# MAIN_IP_ECC_AGGR0_ECC_AGGR register map
Vendor: Texas Instruments
Registers are 32-bit, access not given, reset 0x0 unless marked. A register's access mark holds for its fields unless they carry their own. Offsets are as the file gives them; [hi:lo] are bit positions.

## MAIN_IP_ECC_AGGR0_ECC_AGGR (part 2 of 4)
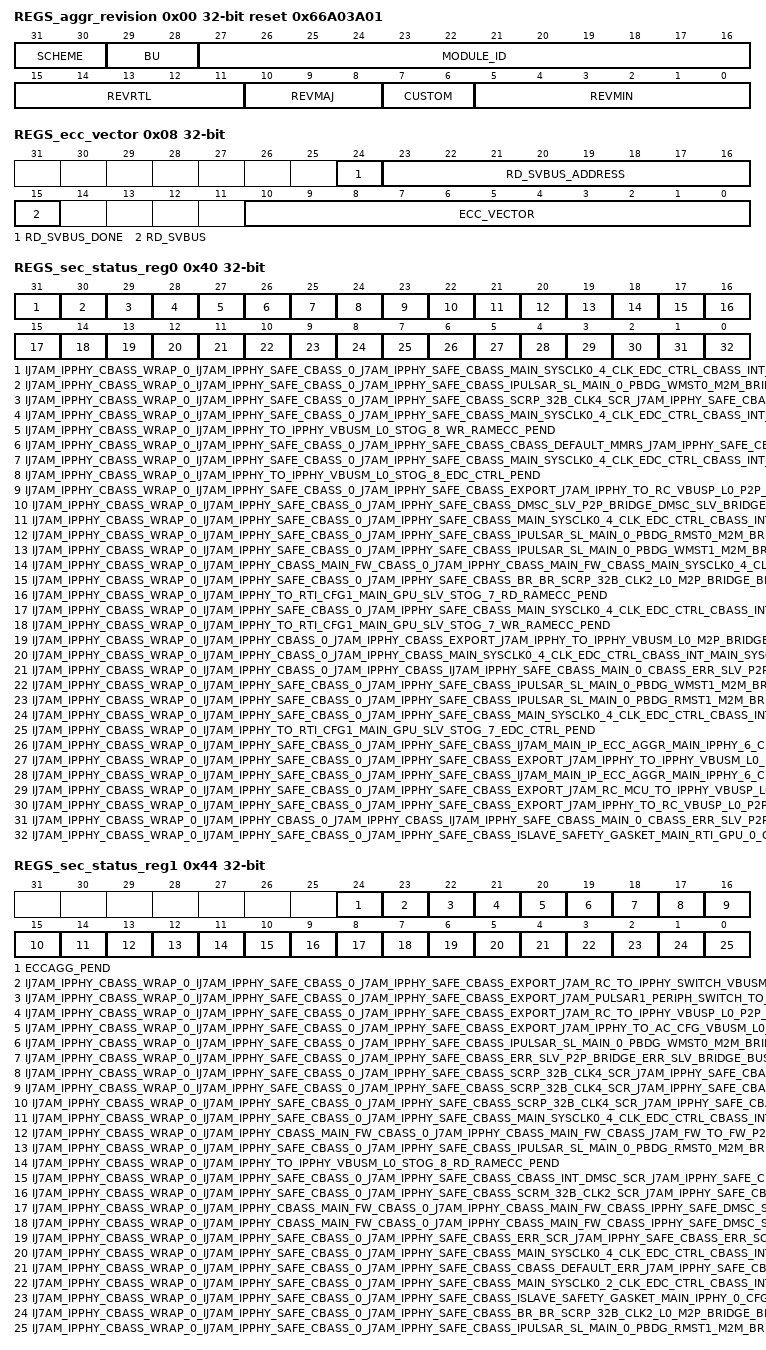
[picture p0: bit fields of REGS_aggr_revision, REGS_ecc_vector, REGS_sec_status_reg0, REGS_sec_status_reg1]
0x00 REGS_aggr_revision ro reset 0x66A03A01 — Revision parameters
  [31:30] SCHEME
  [29:28] BU
  [27:16] MODULE_ID
  [15:11] REVRTL — RTL version
  [10:8] REVMAJ — Major version
  [7:6] CUSTOM — Custom version
  [5:0] REVMIN — Minor version
0x08 REGS_ecc_vector — ECC Vector Register
  [24] RD_SVBUS_DONE — Status to indicate if read on serial VBUS is complete, write of any value will clear this bit. (access R/W1TC)
  [23:16] RD_SVBUS_ADDRESS rw — Read address
  [15] RD_SVBUS — Write 1 to trigger a read on the serial VBUS (access R/W1TS)
  [10:0] ECC_VECTOR rw — Value written to select the corresponding ECC RAM for control or status
0x0C REGS_misc_status ro reset 0x39 — Misc Status
  [10:0] NUM_RAMS — Indicates the number of RAMS serviced by the ECC aggregator
0x10 REGS_reserved_svbus rw — Reference other documents that contain the ECC RAM wrapper and EDC controller serial vbus register sets.
  [31:0] DATA — Serial VBUS register data
0x3C REGS_sec_eoi_reg — EOI Register
  [0] EOI_WR — EOI Register (access R/W1TS)
0x40 REGS_sec_status_reg0 — Interrupt Status Register 0
  [31] IJ7AM_IPPHY_CBASS_WRAP_0_IJ7AM_IPPHY_SAFE_CBASS_0_J7AM_IPPHY_SAFE_CBASS_MAIN_SYSCLK0_4_CLK_EDC_CTRL_CBASS_INT_MAIN_SYSCLK0_4_BUSECC_3_PEND — Interrupt Pending Status for Ij7am_ipphy_cbass_wrap_0_Ij7am_ipphy_safe_cbass_0_j7am_ipphy_safe_cbass_main_SYSCLK0_4_clk_edc_ctrl_cbass_int_main_SYSCLK0_4_busecc_3_pend (access R/W1TS)
  [30] IJ7AM_IPPHY_CBASS_WRAP_0_IJ7AM_IPPHY_SAFE_CBASS_0_J7AM_IPPHY_SAFE_CBASS_IPULSAR_SL_MAIN_0_PBDG_WMST0_M2M_BRIDGE_J7AM_IPPHY_SAFE_CBASS_IPULSAR_SL_MAIN_0_PBDG_WMST0_M2M_BRIDGE_SRC_EDC_CTRL_BUSECC_PEND — Interrupt Pending Status for Ij7am_ipphy_cbass_wrap_0_Ij7am_ipphy_safe_cbass_0_j7am_ipphy_safe_cbass_Ipulsar_sl_main_0_pbdg_wmst0_m2m_bridge_j7am_ipphy_safe_cbass_Ipulsar_sl_main_0_pbdg_wmst0_m2m_bridge_src_edc_ctrl_busecc_pend (access R/W1TS)
  [29] IJ7AM_IPPHY_CBASS_WRAP_0_IJ7AM_IPPHY_SAFE_CBASS_0_J7AM_IPPHY_SAFE_CBASS_SCRP_32B_CLK4_SCR_J7AM_IPPHY_SAFE_CBASS_SCRP_32B_CLK4_SCR_EDC_CTRL_BUSECC_0_PEND — Interrupt Pending Status for Ij7am_ipphy_cbass_wrap_0_Ij7am_ipphy_safe_cbass_0_j7am_ipphy_safe_cbass_scrp_32b_clk4_scr_j7am_ipphy_safe_cbass_scrp_32b_clk4_scr_edc_ctrl_busecc_0_pend (access R/W1TS)
  [28] IJ7AM_IPPHY_CBASS_WRAP_0_IJ7AM_IPPHY_SAFE_CBASS_0_J7AM_IPPHY_SAFE_CBASS_MAIN_SYSCLK0_4_CLK_EDC_CTRL_CBASS_INT_MAIN_SYSCLK0_4_BUSECC_5_PEND — Interrupt Pending Status for Ij7am_ipphy_cbass_wrap_0_Ij7am_ipphy_safe_cbass_0_j7am_ipphy_safe_cbass_main_SYSCLK0_4_clk_edc_ctrl_cbass_int_main_SYSCLK0_4_busecc_5_pend (access R/W1TS)
  [27] IJ7AM_IPPHY_CBASS_WRAP_0_IJ7AM_IPPHY_TO_IPPHY_VBUSM_L0_STOG_8_WR_RAMECC_PEND — Interrupt Pending Status for Ij7am_ipphy_cbass_wrap_0_Ij7am_ipphy_to_ipphy_vbusm_l0_stog_8_wr_ramecc_pend (access R/W1TS)
  [26] IJ7AM_IPPHY_CBASS_WRAP_0_IJ7AM_IPPHY_SAFE_CBASS_0_J7AM_IPPHY_SAFE_CBASS_CBASS_DEFAULT_MMRS_J7AM_IPPHY_SAFE_CBASS_CBASS_DEFAULT_MMRS_EDC_CTRL_BUSECC_PEND — Interrupt Pending Status for Ij7am_ipphy_cbass_wrap_0_Ij7am_ipphy_safe_cbass_0_j7am_ipphy_safe_cbass_cbass_default_mmrs_j7am_ipphy_safe_cbass_cbass_default_mmrs_edc_ctrl_busecc_pend (access R/W1TS)
  [25] IJ7AM_IPPHY_CBASS_WRAP_0_IJ7AM_IPPHY_SAFE_CBASS_0_J7AM_IPPHY_SAFE_CBASS_MAIN_SYSCLK0_4_CLK_EDC_CTRL_CBASS_INT_MAIN_SYSCLK0_4_BUSECC_0_PEND — Interrupt Pending Status for Ij7am_ipphy_cbass_wrap_0_Ij7am_ipphy_safe_cbass_0_j7am_ipphy_safe_cbass_main_SYSCLK0_4_clk_edc_ctrl_cbass_int_main_SYSCLK0_4_busecc_0_pend (access R/W1TS)
  [24] IJ7AM_IPPHY_CBASS_WRAP_0_IJ7AM_IPPHY_TO_IPPHY_VBUSM_L0_STOG_8_EDC_CTRL_PEND — Interrupt Pending Status for Ij7am_ipphy_cbass_wrap_0_Ij7am_ipphy_to_ipphy_vbusm_l0_stog_8_edc_ctrl_pend (access R/W1TS)
  [23] IJ7AM_IPPHY_CBASS_WRAP_0_IJ7AM_IPPHY_SAFE_CBASS_0_J7AM_IPPHY_SAFE_CBASS_EXPORT_J7AM_IPPHY_TO_RC_VBUSP_L0_P2P_BRIDGE_EXPORT_J7AM_IPPHY_TO_RC_VBUSP_L0_BRIDGE_DST_BUSECC_PEND — Interrupt Pending Status for Ij7am_ipphy_cbass_wrap_0_Ij7am_ipphy_safe_cbass_0_j7am_ipphy_safe_cbass_export_j7am_ipphy_to_rc_vbusp_l0_p2p_bridge_export_j7am_ipphy_to_rc_vbusp_l0_bridge_dst_busecc_pend (access R/W1TS)
  [22] IJ7AM_IPPHY_CBASS_WRAP_0_IJ7AM_IPPHY_SAFE_CBASS_0_J7AM_IPPHY_SAFE_CBASS_DMSC_SLV_P2P_BRIDGE_DMSC_SLV_BRIDGE_BUSECC_PEND — Interrupt Pending Status for Ij7am_ipphy_cbass_wrap_0_Ij7am_ipphy_safe_cbass_0_j7am_ipphy_safe_cbass_dmsc_slv_p2p_bridge_dmsc_slv_bridge_busecc_pend (access R/W1TS)
  [21] IJ7AM_IPPHY_CBASS_WRAP_0_IJ7AM_IPPHY_SAFE_CBASS_0_J7AM_IPPHY_SAFE_CBASS_MAIN_SYSCLK0_4_CLK_EDC_CTRL_CBASS_INT_MAIN_SYSCLK0_4_BUSECC_4_PEND — Interrupt Pending Status for Ij7am_ipphy_cbass_wrap_0_Ij7am_ipphy_safe_cbass_0_j7am_ipphy_safe_cbass_main_SYSCLK0_4_clk_edc_ctrl_cbass_int_main_SYSCLK0_4_busecc_4_pend (access R/W1TS)
  [20] IJ7AM_IPPHY_CBASS_WRAP_0_IJ7AM_IPPHY_SAFE_CBASS_0_J7AM_IPPHY_SAFE_CBASS_IPULSAR_SL_MAIN_0_PBDG_RMST0_M2M_BRIDGE_J7AM_IPPHY_SAFE_CBASS_IPULSAR_SL_MAIN_0_PBDG_RMST0_M2M_BRIDGE_SRC_EDC_CTRL_BUSECC_PEND — Interrupt Pending Status for Ij7am_ipphy_cbass_wrap_0_Ij7am_ipphy_safe_cbass_0_j7am_ipphy_safe_cbass_Ipulsar_sl_main_0_pbdg_rmst0_m2m_bridge_j7am_ipphy_safe_cbass_Ipulsar_sl_main_0_pbdg_rmst0_m2m_bridge_src_edc_ctrl_busecc_pend (access R/W1TS)
  [19] IJ7AM_IPPHY_CBASS_WRAP_0_IJ7AM_IPPHY_SAFE_CBASS_0_J7AM_IPPHY_SAFE_CBASS_IPULSAR_SL_MAIN_0_PBDG_WMST1_M2M_BRIDGE_J7AM_IPPHY_SAFE_CBASS_IPULSAR_SL_MAIN_0_PBDG_WMST1_M2M_BRIDGE_SRC_EDC_CTRL_BUSECC_PEND — Interrupt Pending Status for Ij7am_ipphy_cbass_wrap_0_Ij7am_ipphy_safe_cbass_0_j7am_ipphy_safe_cbass_Ipulsar_sl_main_0_pbdg_wmst1_m2m_bridge_j7am_ipphy_safe_cbass_Ipulsar_sl_main_0_pbdg_wmst1_m2m_bridge_src_edc_ctrl_busecc_pend (access R/W1TS)
  [18] IJ7AM_IPPHY_CBASS_WRAP_0_IJ7AM_IPPHY_CBASS_MAIN_FW_CBASS_0_J7AM_IPPHY_CBASS_MAIN_FW_CBASS_MAIN_SYSCLK0_4_CLK_EDC_CTRL_CBASS_INT_MAIN_SYSCLK0_4_BUSECC_PEND — Interrupt Pending Status for Ij7am_ipphy_cbass_wrap_0_Ij7am_ipphy_cbass_main_fw_cbass_0_j7am_ipphy_cbass_main_fw_cbass_main_SYSCLK0_4_clk_edc_ctrl_cbass_int_main_SYSCLK0_4_busecc_pend (access R/W1TS)
  [17] IJ7AM_IPPHY_CBASS_WRAP_0_IJ7AM_IPPHY_SAFE_CBASS_0_J7AM_IPPHY_SAFE_CBASS_BR_BR_SCRP_32B_CLK2_L0_M2P_BRIDGE_BR_BR_SCRP_32B_CLK2_L0_BRIDGE_SRC_BUSECC_PEND — Interrupt Pending Status for Ij7am_ipphy_cbass_wrap_0_Ij7am_ipphy_safe_cbass_0_j7am_ipphy_safe_cbass_br_br_scrp_32b_clk2_l0_m2p_bridge_br_br_scrp_32b_clk2_l0_bridge_src_busecc_pend (access R/W1TS)
  [16] IJ7AM_IPPHY_CBASS_WRAP_0_IJ7AM_IPPHY_TO_RTI_CFG1_MAIN_GPU_SLV_STOG_7_RD_RAMECC_PEND — Interrupt Pending Status for Ij7am_ipphy_cbass_wrap_0_Ij7am_ipphy_to_rti_cfg1_main_gpu_slv_stog_7_rd_ramecc_pend (access R/W1TS)
  [15] IJ7AM_IPPHY_CBASS_WRAP_0_IJ7AM_IPPHY_SAFE_CBASS_0_J7AM_IPPHY_SAFE_CBASS_MAIN_SYSCLK0_4_CLK_EDC_CTRL_CBASS_INT_MAIN_SYSCLK0_4_BUSECC_6_PEND — Interrupt Pending Status for Ij7am_ipphy_cbass_wrap_0_Ij7am_ipphy_safe_cbass_0_j7am_ipphy_safe_cbass_main_SYSCLK0_4_clk_edc_ctrl_cbass_int_main_SYSCLK0_4_busecc_6_pend (access R/W1TS)
  [14] IJ7AM_IPPHY_CBASS_WRAP_0_IJ7AM_IPPHY_TO_RTI_CFG1_MAIN_GPU_SLV_STOG_7_WR_RAMECC_PEND — Interrupt Pending Status for Ij7am_ipphy_cbass_wrap_0_Ij7am_ipphy_to_rti_cfg1_main_gpu_slv_stog_7_wr_ramecc_pend (access R/W1TS)
  [13] IJ7AM_IPPHY_CBASS_WRAP_0_IJ7AM_IPPHY_CBASS_0_J7AM_IPPHY_CBASS_EXPORT_J7AM_IPPHY_TO_IPPHY_VBUSM_L0_M2P_BRIDGE_EXPORT_J7AM_IPPHY_TO_IPPHY_VBUSM_L0_BRIDGE_BUSECC_PEND — Interrupt Pending Status for Ij7am_ipphy_cbass_wrap_0_Ij7am_ipphy_cbass_0_j7am_ipphy_cbass_export_j7am_ipphy_to_ipphy_vbusm_l0_m2p_bridge_export_j7am_ipphy_to_ipphy_vbusm_l0_bridge_busecc_pend (access R/W1TS)
  [12] IJ7AM_IPPHY_CBASS_WRAP_0_IJ7AM_IPPHY_CBASS_0_J7AM_IPPHY_CBASS_MAIN_SYSCLK0_4_CLK_EDC_CTRL_CBASS_INT_MAIN_SYSCLK0_4_BUSECC_PEND — Interrupt Pending Status for Ij7am_ipphy_cbass_wrap_0_Ij7am_ipphy_cbass_0_j7am_ipphy_cbass_main_SYSCLK0_4_clk_edc_ctrl_cbass_int_main_SYSCLK0_4_busecc_pend (access R/W1TS)
  [11] IJ7AM_IPPHY_CBASS_WRAP_0_IJ7AM_IPPHY_CBASS_0_J7AM_IPPHY_CBASS_IJ7AM_IPPHY_SAFE_CBASS_MAIN_0_CBASS_ERR_SLV_P2P_BRIDGE_IJ7AM_IPPHY_SAFE_CBASS_MAIN_0_CBASS_ERR_SLV_BRIDGE_DST_BUSECC_PEND — Interrupt Pending Status for Ij7am_ipphy_cbass_wrap_0_Ij7am_ipphy_cbass_0_j7am_ipphy_cbass_Ij7am_ipphy_safe_cbass_main_0_cbass_err_slv_p2p_bridge_Ij7am_ipphy_safe_cbass_main_0_cbass_err_slv_bridge_dst_busecc_pend (access R/W1TS)
  [10] IJ7AM_IPPHY_CBASS_WRAP_0_IJ7AM_IPPHY_SAFE_CBASS_0_J7AM_IPPHY_SAFE_CBASS_IPULSAR_SL_MAIN_0_PBDG_WMST1_M2M_BRIDGE_J7AM_IPPHY_SAFE_CBASS_IPULSAR_SL_MAIN_0_PBDG_WMST1_M2M_BRIDGE_DST_EDC_CTRL_BUSECC_PEND — Interrupt Pending Status for Ij7am_ipphy_cbass_wrap_0_Ij7am_ipphy_safe_cbass_0_j7am_ipphy_safe_cbass_Ipulsar_sl_main_0_pbdg_wmst1_m2m_bridge_j7am_ipphy_safe_cbass_Ipulsar_sl_main_0_pbdg_wmst1_m2m_bridge_dst_edc_ctrl_busecc_pend (access R/W1TS)
  [9] IJ7AM_IPPHY_CBASS_WRAP_0_IJ7AM_IPPHY_SAFE_CBASS_0_J7AM_IPPHY_SAFE_CBASS_IPULSAR_SL_MAIN_0_PBDG_RMST1_M2M_BRIDGE_J7AM_IPPHY_SAFE_CBASS_IPULSAR_SL_MAIN_0_PBDG_RMST1_M2M_BRIDGE_SRC_EDC_CTRL_BUSECC_PEND — Interrupt Pending Status for Ij7am_ipphy_cbass_wrap_0_Ij7am_ipphy_safe_cbass_0_j7am_ipphy_safe_cbass_Ipulsar_sl_main_0_pbdg_rmst1_m2m_bridge_j7am_ipphy_safe_cbass_Ipulsar_sl_main_0_pbdg_rmst1_m2m_bridge_src_edc_ctrl_busecc_pend (access R/W1TS)
  [8] IJ7AM_IPPHY_CBASS_WRAP_0_IJ7AM_IPPHY_SAFE_CBASS_0_J7AM_IPPHY_SAFE_CBASS_MAIN_SYSCLK0_4_CLK_EDC_CTRL_CBASS_INT_MAIN_SYSCLK0_4_BUSECC_7_PEND — Interrupt Pending Status for Ij7am_ipphy_cbass_wrap_0_Ij7am_ipphy_safe_cbass_0_j7am_ipphy_safe_cbass_main_SYSCLK0_4_clk_edc_ctrl_cbass_int_main_SYSCLK0_4_busecc_7_pend (access R/W1TS)
  [7] IJ7AM_IPPHY_CBASS_WRAP_0_IJ7AM_IPPHY_TO_RTI_CFG1_MAIN_GPU_SLV_STOG_7_EDC_CTRL_PEND — Interrupt Pending Status for Ij7am_ipphy_cbass_wrap_0_Ij7am_ipphy_to_rti_cfg1_main_gpu_slv_stog_7_edc_ctrl_pend (access R/W1TS)
  [6] IJ7AM_IPPHY_CBASS_WRAP_0_IJ7AM_IPPHY_SAFE_CBASS_0_J7AM_IPPHY_SAFE_CBASS_IJ7AM_MAIN_IP_ECC_AGGR_MAIN_IPPHY_6_CFG_P2P_BRIDGE_IJ7AM_MAIN_IP_ECC_AGGR_MAIN_IPPHY_6_CFG_BRIDGE_SRC_BUSECC_PEND — Interrupt Pending Status for Ij7am_ipphy_cbass_wrap_0_Ij7am_ipphy_safe_cbass_0_j7am_ipphy_safe_cbass_Ij7am_main_ip_ecc_aggr_main_ipphy_6_cfg_p2p_bridge_Ij7am_main_ip_ecc_aggr_main_ipphy_6_cfg_bridge_src_busecc_pend (access R/W1TS)
  [5] IJ7AM_IPPHY_CBASS_WRAP_0_IJ7AM_IPPHY_SAFE_CBASS_0_J7AM_IPPHY_SAFE_CBASS_EXPORT_J7AM_IPPHY_TO_IPPHY_VBUSM_L0_P2M_BRIDGE_EXPORT_J7AM_IPPHY_TO_IPPHY_VBUSM_L0_BRIDGE_BUSECC_PEND — Interrupt Pending Status for Ij7am_ipphy_cbass_wrap_0_Ij7am_ipphy_safe_cbass_0_j7am_ipphy_safe_cbass_export_j7am_ipphy_to_ipphy_vbusm_l0_p2m_bridge_export_j7am_ipphy_to_ipphy_vbusm_l0_bridge_busecc_pend (access R/W1TS)
  [4] IJ7AM_IPPHY_CBASS_WRAP_0_IJ7AM_IPPHY_SAFE_CBASS_0_J7AM_IPPHY_SAFE_CBASS_IJ7AM_MAIN_IP_ECC_AGGR_MAIN_IPPHY_6_CFG_P2P_BRIDGE_IJ7AM_MAIN_IP_ECC_AGGR_MAIN_IPPHY_6_CFG_BRIDGE_DST_BUSECC_PEND — Interrupt Pending Status for Ij7am_ipphy_cbass_wrap_0_Ij7am_ipphy_safe_cbass_0_j7am_ipphy_safe_cbass_Ij7am_main_ip_ecc_aggr_main_ipphy_6_cfg_p2p_bridge_Ij7am_main_ip_ecc_aggr_main_ipphy_6_cfg_bridge_dst_busecc_pend (access R/W1TS)
  [3] IJ7AM_IPPHY_CBASS_WRAP_0_IJ7AM_IPPHY_SAFE_CBASS_0_J7AM_IPPHY_SAFE_CBASS_EXPORT_J7AM_RC_MCU_TO_IPPHY_VBUSP_L0_P2P_BRIDGE_EXPORT_J7AM_RC_MCU_TO_IPPHY_VBUSP_L0_BRIDGE_BUSECC_PEND — Interrupt Pending Status for Ij7am_ipphy_cbass_wrap_0_Ij7am_ipphy_safe_cbass_0_j7am_ipphy_safe_cbass_export_j7am_rc_mcu_to_ipphy_vbusp_l0_p2p_bridge_export_j7am_rc_mcu_to_ipphy_vbusp_l0_bridge_busecc_pend (access R/W1TS)
  [2] IJ7AM_IPPHY_CBASS_WRAP_0_IJ7AM_IPPHY_SAFE_CBASS_0_J7AM_IPPHY_SAFE_CBASS_EXPORT_J7AM_IPPHY_TO_RC_VBUSP_L0_P2P_BRIDGE_EXPORT_J7AM_IPPHY_TO_RC_VBUSP_L0_BRIDGE_SRC_BUSECC_PEND — Interrupt Pending Status for Ij7am_ipphy_cbass_wrap_0_Ij7am_ipphy_safe_cbass_0_j7am_ipphy_safe_cbass_export_j7am_ipphy_to_rc_vbusp_l0_p2p_bridge_export_j7am_ipphy_to_rc_vbusp_l0_bridge_src_busecc_pend (access R/W1TS)
  [1] IJ7AM_IPPHY_CBASS_WRAP_0_IJ7AM_IPPHY_CBASS_0_J7AM_IPPHY_CBASS_IJ7AM_IPPHY_SAFE_CBASS_MAIN_0_CBASS_ERR_SLV_P2P_BRIDGE_IJ7AM_IPPHY_SAFE_CBASS_MAIN_0_CBASS_ERR_SLV_BRIDGE_SRC_BUSECC_PEND — Interrupt Pending Status for Ij7am_ipphy_cbass_wrap_0_Ij7am_ipphy_cbass_0_j7am_ipphy_cbass_Ij7am_ipphy_safe_cbass_main_0_cbass_err_slv_p2p_bridge_Ij7am_ipphy_safe_cbass_main_0_cbass_err_slv_bridge_src_busecc_pend (access R/W1TS)
  [0] IJ7AM_IPPHY_CBASS_WRAP_0_IJ7AM_IPPHY_SAFE_CBASS_0_J7AM_IPPHY_SAFE_CBASS_ISLAVE_SAFETY_GASKET_MAIN_RTI_GPU_0_CFG_P2P_BRIDGE_ISLAVE_SAFETY_GASKET_MAIN_RTI_GPU_0_CFG_BRIDGE_BUSECC_PEND — Interrupt Pending Status for Ij7am_ipphy_cbass_wrap_0_Ij7am_ipphy_safe_cbass_0_j7am_ipphy_safe_cbass_Islave_safety_gasket_main_rti_gpu_0_cfg_p2p_bridge_Islave_safety_gasket_main_rti_gpu_0_cfg_bridge_busecc_pend (access R/W1TS)
0x44 REGS_sec_status_reg1 — Interrupt Status Register 1
  [24] ECCAGG_PEND — Interrupt Pending Status for eccagg_pend (access R/W1TS)
  [23] IJ7AM_IPPHY_CBASS_WRAP_0_IJ7AM_IPPHY_SAFE_CBASS_0_J7AM_IPPHY_SAFE_CBASS_EXPORT_J7AM_RC_TO_IPPHY_SWITCH_VBUSM_L0_M2M_BRIDGE_J7AM_IPPHY_SAFE_CBASS_EXPORT_J7AM_RC_TO_IPPHY_SWITCH_VBUSM_L0_M2M_BRIDGE_SRC_EDC_CTRL_BUSECC_PEND — Interrupt Pending Status for Ij7am_ipphy_cbass_wrap_0_Ij7am_ipphy_safe_cbass_0_j7am_ipphy_safe_cbass_export_j7am_rc_to_ipphy_switch_vbusm_l0_m2m_bridge_j7am_ipphy_safe_cbass_export_j7am_rc_to_ipphy_switch_vbusm_l0_m2m_bridge_src_edc_ctrl_busecc_pend (access R/W1TS)
  [22] IJ7AM_IPPHY_CBASS_WRAP_0_IJ7AM_IPPHY_SAFE_CBASS_0_J7AM_IPPHY_SAFE_CBASS_EXPORT_J7AM_PULSAR1_PERIPH_SWITCH_TO_IPPHY_VBUSP_L0_P2P_BRIDGE_EXPORT_J7AM_PULSAR1_PERIPH_SWITCH_TO_IPPHY_VBUSP_L0_BRIDGE_BUSECC_PEND — Interrupt Pending Status for Ij7am_ipphy_cbass_wrap_0_Ij7am_ipphy_safe_cbass_0_j7am_ipphy_safe_cbass_export_j7am_pulsar1_periph_switch_to_ipphy_vbusp_l0_p2p_bridge_export_j7am_pulsar1_periph_switch_to_ipphy_vbusp_l0_bridge_busecc_pend (access R/W1TS)
  [21] IJ7AM_IPPHY_CBASS_WRAP_0_IJ7AM_IPPHY_SAFE_CBASS_0_J7AM_IPPHY_SAFE_CBASS_EXPORT_J7AM_RC_TO_IPPHY_VBUSP_L0_P2P_BRIDGE_EXPORT_J7AM_RC_TO_IPPHY_VBUSP_L0_BRIDGE_BUSECC_PEND — Interrupt Pending Status for Ij7am_ipphy_cbass_wrap_0_Ij7am_ipphy_safe_cbass_0_j7am_ipphy_safe_cbass_export_j7am_rc_to_ipphy_vbusp_l0_p2p_bridge_export_j7am_rc_to_ipphy_vbusp_l0_bridge_busecc_pend (access R/W1TS)
  [20] IJ7AM_IPPHY_CBASS_WRAP_0_IJ7AM_IPPHY_SAFE_CBASS_0_J7AM_IPPHY_SAFE_CBASS_EXPORT_J7AM_IPPHY_TO_AC_CFG_VBUSM_L0_M2M_BRIDGE_J7AM_IPPHY_SAFE_CBASS_EXPORT_J7AM_IPPHY_TO_AC_CFG_VBUSM_L0_M2M_BRIDGE_SRC_EDC_CTRL_BUSECC_PEND — Interrupt Pending Status for Ij7am_ipphy_cbass_wrap_0_Ij7am_ipphy_safe_cbass_0_j7am_ipphy_safe_cbass_export_j7am_ipphy_to_ac_cfg_vbusm_l0_m2m_bridge_j7am_ipphy_safe_cbass_export_j7am_ipphy_to_ac_cfg_vbusm_l0_m2m_bridge_src_edc_ctrl_busecc_pend (access R/W1TS)
  [19] IJ7AM_IPPHY_CBASS_WRAP_0_IJ7AM_IPPHY_SAFE_CBASS_0_J7AM_IPPHY_SAFE_CBASS_IPULSAR_SL_MAIN_0_PBDG_WMST0_M2M_BRIDGE_J7AM_IPPHY_SAFE_CBASS_IPULSAR_SL_MAIN_0_PBDG_WMST0_M2M_BRIDGE_DST_EDC_CTRL_BUSECC_PEND — Interrupt Pending Status for Ij7am_ipphy_cbass_wrap_0_Ij7am_ipphy_safe_cbass_0_j7am_ipphy_safe_cbass_Ipulsar_sl_main_0_pbdg_wmst0_m2m_bridge_j7am_ipphy_safe_cbass_Ipulsar_sl_main_0_pbdg_wmst0_m2m_bridge_dst_edc_ctrl_busecc_pend (access R/W1TS)
  [18] IJ7AM_IPPHY_CBASS_WRAP_0_IJ7AM_IPPHY_SAFE_CBASS_0_J7AM_IPPHY_SAFE_CBASS_ERR_SLV_P2P_BRIDGE_ERR_SLV_BRIDGE_BUSECC_PEND — Interrupt Pending Status for Ij7am_ipphy_cbass_wrap_0_Ij7am_ipphy_safe_cbass_0_j7am_ipphy_safe_cbass_err_slv_p2p_bridge_err_slv_bridge_busecc_pend (access R/W1TS)
  [17] IJ7AM_IPPHY_CBASS_WRAP_0_IJ7AM_IPPHY_SAFE_CBASS_0_J7AM_IPPHY_SAFE_CBASS_SCRP_32B_CLK4_SCR_J7AM_IPPHY_SAFE_CBASS_SCRP_32B_CLK4_SCR_EDC_CTRL_BUSECC_2_PEND — Interrupt Pending Status for Ij7am_ipphy_cbass_wrap_0_Ij7am_ipphy_safe_cbass_0_j7am_ipphy_safe_cbass_scrp_32b_clk4_scr_j7am_ipphy_safe_cbass_scrp_32b_clk4_scr_edc_ctrl_busecc_2_pend (access R/W1TS)
  [16] IJ7AM_IPPHY_CBASS_WRAP_0_IJ7AM_IPPHY_SAFE_CBASS_0_J7AM_IPPHY_SAFE_CBASS_SCRP_32B_CLK4_SCR_J7AM_IPPHY_SAFE_CBASS_SCRP_32B_CLK4_SCR_EDC_CTRL_BUSECC_3_PEND — Interrupt Pending Status for Ij7am_ipphy_cbass_wrap_0_Ij7am_ipphy_safe_cbass_0_j7am_ipphy_safe_cbass_scrp_32b_clk4_scr_j7am_ipphy_safe_cbass_scrp_32b_clk4_scr_edc_ctrl_busecc_3_pend (access R/W1TS)
  [15] IJ7AM_IPPHY_CBASS_WRAP_0_IJ7AM_IPPHY_SAFE_CBASS_0_J7AM_IPPHY_SAFE_CBASS_SCRP_32B_CLK4_SCR_J7AM_IPPHY_SAFE_CBASS_SCRP_32B_CLK4_SCR_EDC_CTRL_BUSECC_1_PEND — Interrupt Pending Status for Ij7am_ipphy_cbass_wrap_0_Ij7am_ipphy_safe_cbass_0_j7am_ipphy_safe_cbass_scrp_32b_clk4_scr_j7am_ipphy_safe_cbass_scrp_32b_clk4_scr_edc_ctrl_busecc_1_pend (access R/W1TS)
  [14] IJ7AM_IPPHY_CBASS_WRAP_0_IJ7AM_IPPHY_SAFE_CBASS_0_J7AM_IPPHY_SAFE_CBASS_MAIN_SYSCLK0_4_CLK_EDC_CTRL_CBASS_INT_MAIN_SYSCLK0_4_BUSECC_2_PEND — Interrupt Pending Status for Ij7am_ipphy_cbass_wrap_0_Ij7am_ipphy_safe_cbass_0_j7am_ipphy_safe_cbass_main_SYSCLK0_4_clk_edc_ctrl_cbass_int_main_SYSCLK0_4_busecc_2_pend (access R/W1TS)
  [13] IJ7AM_IPPHY_CBASS_WRAP_0_IJ7AM_IPPHY_CBASS_MAIN_FW_CBASS_0_J7AM_IPPHY_CBASS_MAIN_FW_CBASS_J7AM_FW_TO_FW_P2P_BRIDGE_J7AM_FW_TO_FW_BRIDGE_BUSECC_PEND — Interrupt Pending Status for Ij7am_ipphy_cbass_wrap_0_Ij7am_ipphy_cbass_main_fw_cbass_0_j7am_ipphy_cbass_main_fw_cbass_j7am_fw_to_fw_p2p_bridge_j7am_fw_to_fw_bridge_busecc_pend (access R/W1TS)
  [12] IJ7AM_IPPHY_CBASS_WRAP_0_IJ7AM_IPPHY_SAFE_CBASS_0_J7AM_IPPHY_SAFE_CBASS_IPULSAR_SL_MAIN_0_PBDG_RMST0_M2M_BRIDGE_J7AM_IPPHY_SAFE_CBASS_IPULSAR_SL_MAIN_0_PBDG_RMST0_M2M_BRIDGE_DST_EDC_CTRL_BUSECC_PEND — Interrupt Pending Status for Ij7am_ipphy_cbass_wrap_0_Ij7am_ipphy_safe_cbass_0_j7am_ipphy_safe_cbass_Ipulsar_sl_main_0_pbdg_rmst0_m2m_bridge_j7am_ipphy_safe_cbass_Ipulsar_sl_main_0_pbdg_rmst0_m2m_bridge_dst_edc_ctrl_busecc_pend (access R/W1TS)
  [11] IJ7AM_IPPHY_CBASS_WRAP_0_IJ7AM_IPPHY_TO_IPPHY_VBUSM_L0_STOG_8_RD_RAMECC_PEND — Interrupt Pending Status for Ij7am_ipphy_cbass_wrap_0_Ij7am_ipphy_to_ipphy_vbusm_l0_stog_8_rd_ramecc_pend (access R/W1TS)
  [10] IJ7AM_IPPHY_CBASS_WRAP_0_IJ7AM_IPPHY_SAFE_CBASS_0_J7AM_IPPHY_SAFE_CBASS_CBASS_INT_DMSC_SCR_J7AM_IPPHY_SAFE_CBASS_CBASS_INT_DMSC_SCR_EDC_CTRL_BUSECC_PEND — Interrupt Pending Status for Ij7am_ipphy_cbass_wrap_0_Ij7am_ipphy_safe_cbass_0_j7am_ipphy_safe_cbass_cbass_int_dmsc_scr_j7am_ipphy_safe_cbass_cbass_int_dmsc_scr_edc_ctrl_busecc_pend (access R/W1TS)
  [9] IJ7AM_IPPHY_CBASS_WRAP_0_IJ7AM_IPPHY_SAFE_CBASS_0_J7AM_IPPHY_SAFE_CBASS_SCRM_32B_CLK2_SCR_J7AM_IPPHY_SAFE_CBASS_SCRM_32B_CLK2_SCR_EDC_CTRL_BUSECC_PEND — Interrupt Pending Status for Ij7am_ipphy_cbass_wrap_0_Ij7am_ipphy_safe_cbass_0_j7am_ipphy_safe_cbass_scrm_32b_clk2_scr_j7am_ipphy_safe_cbass_scrm_32b_clk2_scr_edc_ctrl_busecc_pend (access R/W1TS)
  [8] IJ7AM_IPPHY_CBASS_WRAP_0_IJ7AM_IPPHY_CBASS_MAIN_FW_CBASS_0_J7AM_IPPHY_CBASS_MAIN_FW_CBASS_IPPHY_SAFE_DMSC_SLV_P2P_BRIDGE_IPPHY_SAFE_DMSC_SLV_BRIDGE_SRC_BUSECC_PEND — Interrupt Pending Status for Ij7am_ipphy_cbass_wrap_0_Ij7am_ipphy_cbass_main_fw_cbass_0_j7am_ipphy_cbass_main_fw_cbass_ipphy_safe_dmsc_slv_p2p_bridge_ipphy_safe_dmsc_slv_bridge_src_busecc_pend (access R/W1TS)
  [7] IJ7AM_IPPHY_CBASS_WRAP_0_IJ7AM_IPPHY_CBASS_MAIN_FW_CBASS_0_J7AM_IPPHY_CBASS_MAIN_FW_CBASS_IPPHY_SAFE_DMSC_SLV_P2P_BRIDGE_IPPHY_SAFE_DMSC_SLV_BRIDGE_DST_BUSECC_PEND — Interrupt Pending Status for Ij7am_ipphy_cbass_wrap_0_Ij7am_ipphy_cbass_main_fw_cbass_0_j7am_ipphy_cbass_main_fw_cbass_ipphy_safe_dmsc_slv_p2p_bridge_ipphy_safe_dmsc_slv_bridge_dst_busecc_pend (access R/W1TS)
  [6] IJ7AM_IPPHY_CBASS_WRAP_0_IJ7AM_IPPHY_SAFE_CBASS_0_J7AM_IPPHY_SAFE_CBASS_ERR_SCR_J7AM_IPPHY_SAFE_CBASS_ERR_SCR_EDC_CTRL_BUSECC_PEND — Interrupt Pending Status for Ij7am_ipphy_cbass_wrap_0_Ij7am_ipphy_safe_cbass_0_j7am_ipphy_safe_cbass_err_scr_j7am_ipphy_safe_cbass_err_scr_edc_ctrl_busecc_pend (access R/W1TS)
  [5] IJ7AM_IPPHY_CBASS_WRAP_0_IJ7AM_IPPHY_SAFE_CBASS_0_J7AM_IPPHY_SAFE_CBASS_MAIN_SYSCLK0_4_CLK_EDC_CTRL_CBASS_INT_MAIN_SYSCLK0_4_BUSECC_1_PEND — Interrupt Pending Status for Ij7am_ipphy_cbass_wrap_0_Ij7am_ipphy_safe_cbass_0_j7am_ipphy_safe_cbass_main_SYSCLK0_4_clk_edc_ctrl_cbass_int_main_SYSCLK0_4_busecc_1_pend (access R/W1TS)
  [4] IJ7AM_IPPHY_CBASS_WRAP_0_IJ7AM_IPPHY_SAFE_CBASS_0_J7AM_IPPHY_SAFE_CBASS_CBASS_DEFAULT_ERR_J7AM_IPPHY_SAFE_CBASS_CBASS_DEFAULT_ERR_EDC_CTRL_BUSECC_PEND — Interrupt Pending Status for Ij7am_ipphy_cbass_wrap_0_Ij7am_ipphy_safe_cbass_0_j7am_ipphy_safe_cbass_cbass_default_err_j7am_ipphy_safe_cbass_cbass_default_err_edc_ctrl_busecc_pend (access R/W1TS)
  [3] IJ7AM_IPPHY_CBASS_WRAP_0_IJ7AM_IPPHY_SAFE_CBASS_0_J7AM_IPPHY_SAFE_CBASS_MAIN_SYSCLK0_2_CLK_EDC_CTRL_CBASS_INT_MAIN_SYSCLK0_2_BUSECC_PEND — Interrupt Pending Status for Ij7am_ipphy_cbass_wrap_0_Ij7am_ipphy_safe_cbass_0_j7am_ipphy_safe_cbass_main_SYSCLK0_2_clk_edc_ctrl_cbass_int_main_SYSCLK0_2_busecc_pend (access R/W1TS)
  [2] IJ7AM_IPPHY_CBASS_WRAP_0_IJ7AM_IPPHY_SAFE_CBASS_0_J7AM_IPPHY_SAFE_CBASS_ISLAVE_SAFETY_GASKET_MAIN_IPPHY_0_CFG_P2P_BRIDGE_ISLAVE_SAFETY_GASKET_MAIN_IPPHY_0_CFG_BRIDGE_BUSECC_PEND — Interrupt Pending Status for Ij7am_ipphy_cbass_wrap_0_Ij7am_ipphy_safe_cbass_0_j7am_ipphy_safe_cbass_Islave_safety_gasket_main_ipphy_0_cfg_p2p_bridge_Islave_safety_gasket_main_ipphy_0_cfg_bridge_busecc_pend (access R/W1TS)
  [1] IJ7AM_IPPHY_CBASS_WRAP_0_IJ7AM_IPPHY_SAFE_CBASS_0_J7AM_IPPHY_SAFE_CBASS_BR_BR_SCRP_32B_CLK2_L0_M2P_BRIDGE_BR_BR_SCRP_32B_CLK2_L0_BRIDGE_DST_BUSECC_PEND — Interrupt Pending Status for Ij7am_ipphy_cbass_wrap_0_Ij7am_ipphy_safe_cbass_0_j7am_ipphy_safe_cbass_br_br_scrp_32b_clk2_l0_m2p_bridge_br_br_scrp_32b_clk2_l0_bridge_dst_busecc_pend (access R/W1TS)
  [0] IJ7AM_IPPHY_CBASS_WRAP_0_IJ7AM_IPPHY_SAFE_CBASS_0_J7AM_IPPHY_SAFE_CBASS_IPULSAR_SL_MAIN_0_PBDG_RMST1_M2M_BRIDGE_J7AM_IPPHY_SAFE_CBASS_IPULSAR_SL_MAIN_0_PBDG_RMST1_M2M_BRIDGE_DST_EDC_CTRL_BUSECC_PEND — Interrupt Pending Status for Ij7am_ipphy_cbass_wrap_0_Ij7am_ipphy_safe_cbass_0_j7am_ipphy_safe_cbass_Ipulsar_sl_main_0_pbdg_rmst1_m2m_bridge_j7am_ipphy_safe_cbass_Ipulsar_sl_main_0_pbdg_rmst1_m2m_bridge_dst_edc_ctrl_busecc_pend (access R/W1TS)
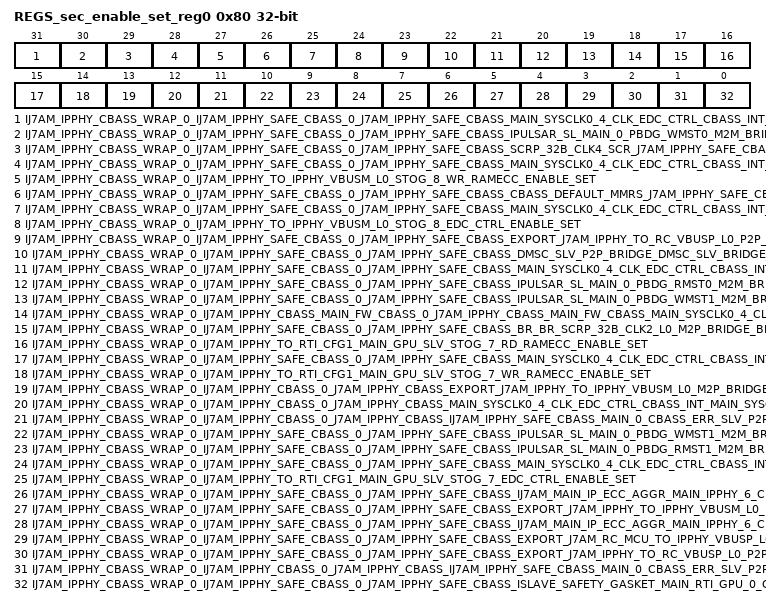
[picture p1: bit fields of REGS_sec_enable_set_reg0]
0x80 REGS_sec_enable_set_reg0 — Interrupt Enable Set Register 0
  [31] IJ7AM_IPPHY_CBASS_WRAP_0_IJ7AM_IPPHY_SAFE_CBASS_0_J7AM_IPPHY_SAFE_CBASS_MAIN_SYSCLK0_4_CLK_EDC_CTRL_CBASS_INT_MAIN_SYSCLK0_4_BUSECC_3_ENABLE_SET — Interrupt Enable Set Register for Ij7am_ipphy_cbass_wrap_0_Ij7am_ipphy_safe_cbass_0_j7am_ipphy_safe_cbass_main_SYSCLK0_4_clk_edc_ctrl_cbass_int_main_SYSCLK0_4_busecc_3_pend (access R/W1TS)
  [30] IJ7AM_IPPHY_CBASS_WRAP_0_IJ7AM_IPPHY_SAFE_CBASS_0_J7AM_IPPHY_SAFE_CBASS_IPULSAR_SL_MAIN_0_PBDG_WMST0_M2M_BRIDGE_J7AM_IPPHY_SAFE_CBASS_IPULSAR_SL_MAIN_0_PBDG_WMST0_M2M_BRIDGE_SRC_EDC_CTRL_BUSECC_ENABLE_SET — Interrupt Enable Set Register for Ij7am_ipphy_cbass_wrap_0_Ij7am_ipphy_safe_cbass_0_j7am_ipphy_safe_cbass_Ipulsar_sl_main_0_pbdg_wmst0_m2m_bridge_j7am_ipphy_safe_cbass_Ipulsar_sl_main_0_pbdg_wmst0_m2m_bridge_src_edc_ctrl_busecc_pend (access R/W1TS)
  [29] IJ7AM_IPPHY_CBASS_WRAP_0_IJ7AM_IPPHY_SAFE_CBASS_0_J7AM_IPPHY_SAFE_CBASS_SCRP_32B_CLK4_SCR_J7AM_IPPHY_SAFE_CBASS_SCRP_32B_CLK4_SCR_EDC_CTRL_BUSECC_0_ENABLE_SET — Interrupt Enable Set Register for Ij7am_ipphy_cbass_wrap_0_Ij7am_ipphy_safe_cbass_0_j7am_ipphy_safe_cbass_scrp_32b_clk4_scr_j7am_ipphy_safe_cbass_scrp_32b_clk4_scr_edc_ctrl_busecc_0_pend (access R/W1TS)
  [28] IJ7AM_IPPHY_CBASS_WRAP_0_IJ7AM_IPPHY_SAFE_CBASS_0_J7AM_IPPHY_SAFE_CBASS_MAIN_SYSCLK0_4_CLK_EDC_CTRL_CBASS_INT_MAIN_SYSCLK0_4_BUSECC_5_ENABLE_SET — Interrupt Enable Set Register for Ij7am_ipphy_cbass_wrap_0_Ij7am_ipphy_safe_cbass_0_j7am_ipphy_safe_cbass_main_SYSCLK0_4_clk_edc_ctrl_cbass_int_main_SYSCLK0_4_busecc_5_pend (access R/W1TS)
  [27] IJ7AM_IPPHY_CBASS_WRAP_0_IJ7AM_IPPHY_TO_IPPHY_VBUSM_L0_STOG_8_WR_RAMECC_ENABLE_SET — Interrupt Enable Set Register for Ij7am_ipphy_cbass_wrap_0_Ij7am_ipphy_to_ipphy_vbusm_l0_stog_8_wr_ramecc_pend (access R/W1TS)
  [26] IJ7AM_IPPHY_CBASS_WRAP_0_IJ7AM_IPPHY_SAFE_CBASS_0_J7AM_IPPHY_SAFE_CBASS_CBASS_DEFAULT_MMRS_J7AM_IPPHY_SAFE_CBASS_CBASS_DEFAULT_MMRS_EDC_CTRL_BUSECC_ENABLE_SET — Interrupt Enable Set Register for Ij7am_ipphy_cbass_wrap_0_Ij7am_ipphy_safe_cbass_0_j7am_ipphy_safe_cbass_cbass_default_mmrs_j7am_ipphy_safe_cbass_cbass_default_mmrs_edc_ctrl_busecc_pend (access R/W1TS)
  [25] IJ7AM_IPPHY_CBASS_WRAP_0_IJ7AM_IPPHY_SAFE_CBASS_0_J7AM_IPPHY_SAFE_CBASS_MAIN_SYSCLK0_4_CLK_EDC_CTRL_CBASS_INT_MAIN_SYSCLK0_4_BUSECC_0_ENABLE_SET — Interrupt Enable Set Register for Ij7am_ipphy_cbass_wrap_0_Ij7am_ipphy_safe_cbass_0_j7am_ipphy_safe_cbass_main_SYSCLK0_4_clk_edc_ctrl_cbass_int_main_SYSCLK0_4_busecc_0_pend (access R/W1TS)
  [24] IJ7AM_IPPHY_CBASS_WRAP_0_IJ7AM_IPPHY_TO_IPPHY_VBUSM_L0_STOG_8_EDC_CTRL_ENABLE_SET — Interrupt Enable Set Register for Ij7am_ipphy_cbass_wrap_0_Ij7am_ipphy_to_ipphy_vbusm_l0_stog_8_edc_ctrl_pend (access R/W1TS)
  [23] IJ7AM_IPPHY_CBASS_WRAP_0_IJ7AM_IPPHY_SAFE_CBASS_0_J7AM_IPPHY_SAFE_CBASS_EXPORT_J7AM_IPPHY_TO_RC_VBUSP_L0_P2P_BRIDGE_EXPORT_J7AM_IPPHY_TO_RC_VBUSP_L0_BRIDGE_DST_BUSECC_ENABLE_SET — Interrupt Enable Set Register for Ij7am_ipphy_cbass_wrap_0_Ij7am_ipphy_safe_cbass_0_j7am_ipphy_safe_cbass_export_j7am_ipphy_to_rc_vbusp_l0_p2p_bridge_export_j7am_ipphy_to_rc_vbusp_l0_bridge_dst_busecc_pend (access R/W1TS)
  [22] IJ7AM_IPPHY_CBASS_WRAP_0_IJ7AM_IPPHY_SAFE_CBASS_0_J7AM_IPPHY_SAFE_CBASS_DMSC_SLV_P2P_BRIDGE_DMSC_SLV_BRIDGE_BUSECC_ENABLE_SET — Interrupt Enable Set Register for Ij7am_ipphy_cbass_wrap_0_Ij7am_ipphy_safe_cbass_0_j7am_ipphy_safe_cbass_dmsc_slv_p2p_bridge_dmsc_slv_bridge_busecc_pend (access R/W1TS)
  [21] IJ7AM_IPPHY_CBASS_WRAP_0_IJ7AM_IPPHY_SAFE_CBASS_0_J7AM_IPPHY_SAFE_CBASS_MAIN_SYSCLK0_4_CLK_EDC_CTRL_CBASS_INT_MAIN_SYSCLK0_4_BUSECC_4_ENABLE_SET — Interrupt Enable Set Register for Ij7am_ipphy_cbass_wrap_0_Ij7am_ipphy_safe_cbass_0_j7am_ipphy_safe_cbass_main_SYSCLK0_4_clk_edc_ctrl_cbass_int_main_SYSCLK0_4_busecc_4_pend (access R/W1TS)
  [20] IJ7AM_IPPHY_CBASS_WRAP_0_IJ7AM_IPPHY_SAFE_CBASS_0_J7AM_IPPHY_SAFE_CBASS_IPULSAR_SL_MAIN_0_PBDG_RMST0_M2M_BRIDGE_J7AM_IPPHY_SAFE_CBASS_IPULSAR_SL_MAIN_0_PBDG_RMST0_M2M_BRIDGE_SRC_EDC_CTRL_BUSECC_ENABLE_SET — Interrupt Enable Set Register for Ij7am_ipphy_cbass_wrap_0_Ij7am_ipphy_safe_cbass_0_j7am_ipphy_safe_cbass_Ipulsar_sl_main_0_pbdg_rmst0_m2m_bridge_j7am_ipphy_safe_cbass_Ipulsar_sl_main_0_pbdg_rmst0_m2m_bridge_src_edc_ctrl_busecc_pend (access R/W1TS)
  [19] IJ7AM_IPPHY_CBASS_WRAP_0_IJ7AM_IPPHY_SAFE_CBASS_0_J7AM_IPPHY_SAFE_CBASS_IPULSAR_SL_MAIN_0_PBDG_WMST1_M2M_BRIDGE_J7AM_IPPHY_SAFE_CBASS_IPULSAR_SL_MAIN_0_PBDG_WMST1_M2M_BRIDGE_SRC_EDC_CTRL_BUSECC_ENABLE_SET — Interrupt Enable Set Register for Ij7am_ipphy_cbass_wrap_0_Ij7am_ipphy_safe_cbass_0_j7am_ipphy_safe_cbass_Ipulsar_sl_main_0_pbdg_wmst1_m2m_bridge_j7am_ipphy_safe_cbass_Ipulsar_sl_main_0_pbdg_wmst1_m2m_bridge_src_edc_ctrl_busecc_pend (access R/W1TS)
  [18] IJ7AM_IPPHY_CBASS_WRAP_0_IJ7AM_IPPHY_CBASS_MAIN_FW_CBASS_0_J7AM_IPPHY_CBASS_MAIN_FW_CBASS_MAIN_SYSCLK0_4_CLK_EDC_CTRL_CBASS_INT_MAIN_SYSCLK0_4_BUSECC_ENABLE_SET — Interrupt Enable Set Register for Ij7am_ipphy_cbass_wrap_0_Ij7am_ipphy_cbass_main_fw_cbass_0_j7am_ipphy_cbass_main_fw_cbass_main_SYSCLK0_4_clk_edc_ctrl_cbass_int_main_SYSCLK0_4_busecc_pend (access R/W1TS)
  [17] IJ7AM_IPPHY_CBASS_WRAP_0_IJ7AM_IPPHY_SAFE_CBASS_0_J7AM_IPPHY_SAFE_CBASS_BR_BR_SCRP_32B_CLK2_L0_M2P_BRIDGE_BR_BR_SCRP_32B_CLK2_L0_BRIDGE_SRC_BUSECC_ENABLE_SET — Interrupt Enable Set Register for Ij7am_ipphy_cbass_wrap_0_Ij7am_ipphy_safe_cbass_0_j7am_ipphy_safe_cbass_br_br_scrp_32b_clk2_l0_m2p_bridge_br_br_scrp_32b_clk2_l0_bridge_src_busecc_pend (access R/W1TS)
  [16] IJ7AM_IPPHY_CBASS_WRAP_0_IJ7AM_IPPHY_TO_RTI_CFG1_MAIN_GPU_SLV_STOG_7_RD_RAMECC_ENABLE_SET — Interrupt Enable Set Register for Ij7am_ipphy_cbass_wrap_0_Ij7am_ipphy_to_rti_cfg1_main_gpu_slv_stog_7_rd_ramecc_pend (access R/W1TS)
  [15] IJ7AM_IPPHY_CBASS_WRAP_0_IJ7AM_IPPHY_SAFE_CBASS_0_J7AM_IPPHY_SAFE_CBASS_MAIN_SYSCLK0_4_CLK_EDC_CTRL_CBASS_INT_MAIN_SYSCLK0_4_BUSECC_6_ENABLE_SET — Interrupt Enable Set Register for Ij7am_ipphy_cbass_wrap_0_Ij7am_ipphy_safe_cbass_0_j7am_ipphy_safe_cbass_main_SYSCLK0_4_clk_edc_ctrl_cbass_int_main_SYSCLK0_4_busecc_6_pend (access R/W1TS)
  [14] IJ7AM_IPPHY_CBASS_WRAP_0_IJ7AM_IPPHY_TO_RTI_CFG1_MAIN_GPU_SLV_STOG_7_WR_RAMECC_ENABLE_SET — Interrupt Enable Set Register for Ij7am_ipphy_cbass_wrap_0_Ij7am_ipphy_to_rti_cfg1_main_gpu_slv_stog_7_wr_ramecc_pend (access R/W1TS)
  [13] IJ7AM_IPPHY_CBASS_WRAP_0_IJ7AM_IPPHY_CBASS_0_J7AM_IPPHY_CBASS_EXPORT_J7AM_IPPHY_TO_IPPHY_VBUSM_L0_M2P_BRIDGE_EXPORT_J7AM_IPPHY_TO_IPPHY_VBUSM_L0_BRIDGE_BUSECC_ENABLE_SET — Interrupt Enable Set Register for Ij7am_ipphy_cbass_wrap_0_Ij7am_ipphy_cbass_0_j7am_ipphy_cbass_export_j7am_ipphy_to_ipphy_vbusm_l0_m2p_bridge_export_j7am_ipphy_to_ipphy_vbusm_l0_bridge_busecc_pend (access R/W1TS)
  [12] IJ7AM_IPPHY_CBASS_WRAP_0_IJ7AM_IPPHY_CBASS_0_J7AM_IPPHY_CBASS_MAIN_SYSCLK0_4_CLK_EDC_CTRL_CBASS_INT_MAIN_SYSCLK0_4_BUSECC_ENABLE_SET — Interrupt Enable Set Register for Ij7am_ipphy_cbass_wrap_0_Ij7am_ipphy_cbass_0_j7am_ipphy_cbass_main_SYSCLK0_4_clk_edc_ctrl_cbass_int_main_SYSCLK0_4_busecc_pend (access R/W1TS)
  [11] IJ7AM_IPPHY_CBASS_WRAP_0_IJ7AM_IPPHY_CBASS_0_J7AM_IPPHY_CBASS_IJ7AM_IPPHY_SAFE_CBASS_MAIN_0_CBASS_ERR_SLV_P2P_BRIDGE_IJ7AM_IPPHY_SAFE_CBASS_MAIN_0_CBASS_ERR_SLV_BRIDGE_DST_BUSECC_ENABLE_SET — Interrupt Enable Set Register for Ij7am_ipphy_cbass_wrap_0_Ij7am_ipphy_cbass_0_j7am_ipphy_cbass_Ij7am_ipphy_safe_cbass_main_0_cbass_err_slv_p2p_bridge_Ij7am_ipphy_safe_cbass_main_0_cbass_err_slv_bridge_dst_busecc_pend (access R/W1TS)
  [10] IJ7AM_IPPHY_CBASS_WRAP_0_IJ7AM_IPPHY_SAFE_CBASS_0_J7AM_IPPHY_SAFE_CBASS_IPULSAR_SL_MAIN_0_PBDG_WMST1_M2M_BRIDGE_J7AM_IPPHY_SAFE_CBASS_IPULSAR_SL_MAIN_0_PBDG_WMST1_M2M_BRIDGE_DST_EDC_CTRL_BUSECC_ENABLE_SET — Interrupt Enable Set Register for Ij7am_ipphy_cbass_wrap_0_Ij7am_ipphy_safe_cbass_0_j7am_ipphy_safe_cbass_Ipulsar_sl_main_0_pbdg_wmst1_m2m_bridge_j7am_ipphy_safe_cbass_Ipulsar_sl_main_0_pbdg_wmst1_m2m_bridge_dst_edc_ctrl_busecc_pend (access R/W1TS)
  [9] IJ7AM_IPPHY_CBASS_WRAP_0_IJ7AM_IPPHY_SAFE_CBASS_0_J7AM_IPPHY_SAFE_CBASS_IPULSAR_SL_MAIN_0_PBDG_RMST1_M2M_BRIDGE_J7AM_IPPHY_SAFE_CBASS_IPULSAR_SL_MAIN_0_PBDG_RMST1_M2M_BRIDGE_SRC_EDC_CTRL_BUSECC_ENABLE_SET — Interrupt Enable Set Register for Ij7am_ipphy_cbass_wrap_0_Ij7am_ipphy_safe_cbass_0_j7am_ipphy_safe_cbass_Ipulsar_sl_main_0_pbdg_rmst1_m2m_bridge_j7am_ipphy_safe_cbass_Ipulsar_sl_main_0_pbdg_rmst1_m2m_bridge_src_edc_ctrl_busecc_pend (access R/W1TS)
  [8] IJ7AM_IPPHY_CBASS_WRAP_0_IJ7AM_IPPHY_SAFE_CBASS_0_J7AM_IPPHY_SAFE_CBASS_MAIN_SYSCLK0_4_CLK_EDC_CTRL_CBASS_INT_MAIN_SYSCLK0_4_BUSECC_7_ENABLE_SET — Interrupt Enable Set Register for Ij7am_ipphy_cbass_wrap_0_Ij7am_ipphy_safe_cbass_0_j7am_ipphy_safe_cbass_main_SYSCLK0_4_clk_edc_ctrl_cbass_int_main_SYSCLK0_4_busecc_7_pend (access R/W1TS)
  [7] IJ7AM_IPPHY_CBASS_WRAP_0_IJ7AM_IPPHY_TO_RTI_CFG1_MAIN_GPU_SLV_STOG_7_EDC_CTRL_ENABLE_SET — Interrupt Enable Set Register for Ij7am_ipphy_cbass_wrap_0_Ij7am_ipphy_to_rti_cfg1_main_gpu_slv_stog_7_edc_ctrl_pend (access R/W1TS)
  [6] IJ7AM_IPPHY_CBASS_WRAP_0_IJ7AM_IPPHY_SAFE_CBASS_0_J7AM_IPPHY_SAFE_CBASS_IJ7AM_MAIN_IP_ECC_AGGR_MAIN_IPPHY_6_CFG_P2P_BRIDGE_IJ7AM_MAIN_IP_ECC_AGGR_MAIN_IPPHY_6_CFG_BRIDGE_SRC_BUSECC_ENABLE_SET — Interrupt Enable Set Register for Ij7am_ipphy_cbass_wrap_0_Ij7am_ipphy_safe_cbass_0_j7am_ipphy_safe_cbass_Ij7am_main_ip_ecc_aggr_main_ipphy_6_cfg_p2p_bridge_Ij7am_main_ip_ecc_aggr_main_ipphy_6_cfg_bridge_src_busecc_pend (access R/W1TS)
  [5] IJ7AM_IPPHY_CBASS_WRAP_0_IJ7AM_IPPHY_SAFE_CBASS_0_J7AM_IPPHY_SAFE_CBASS_EXPORT_J7AM_IPPHY_TO_IPPHY_VBUSM_L0_P2M_BRIDGE_EXPORT_J7AM_IPPHY_TO_IPPHY_VBUSM_L0_BRIDGE_BUSECC_ENABLE_SET — Interrupt Enable Set Register for Ij7am_ipphy_cbass_wrap_0_Ij7am_ipphy_safe_cbass_0_j7am_ipphy_safe_cbass_export_j7am_ipphy_to_ipphy_vbusm_l0_p2m_bridge_export_j7am_ipphy_to_ipphy_vbusm_l0_bridge_busecc_pend (access R/W1TS)
  [4] IJ7AM_IPPHY_CBASS_WRAP_0_IJ7AM_IPPHY_SAFE_CBASS_0_J7AM_IPPHY_SAFE_CBASS_IJ7AM_MAIN_IP_ECC_AGGR_MAIN_IPPHY_6_CFG_P2P_BRIDGE_IJ7AM_MAIN_IP_ECC_AGGR_MAIN_IPPHY_6_CFG_BRIDGE_DST_BUSECC_ENABLE_SET — Interrupt Enable Set Register for Ij7am_ipphy_cbass_wrap_0_Ij7am_ipphy_safe_cbass_0_j7am_ipphy_safe_cbass_Ij7am_main_ip_ecc_aggr_main_ipphy_6_cfg_p2p_bridge_Ij7am_main_ip_ecc_aggr_main_ipphy_6_cfg_bridge_dst_busecc_pend (access R/W1TS)
  [3] IJ7AM_IPPHY_CBASS_WRAP_0_IJ7AM_IPPHY_SAFE_CBASS_0_J7AM_IPPHY_SAFE_CBASS_EXPORT_J7AM_RC_MCU_TO_IPPHY_VBUSP_L0_P2P_BRIDGE_EXPORT_J7AM_RC_MCU_TO_IPPHY_VBUSP_L0_BRIDGE_BUSECC_ENABLE_SET — Interrupt Enable Set Register for Ij7am_ipphy_cbass_wrap_0_Ij7am_ipphy_safe_cbass_0_j7am_ipphy_safe_cbass_export_j7am_rc_mcu_to_ipphy_vbusp_l0_p2p_bridge_export_j7am_rc_mcu_to_ipphy_vbusp_l0_bridge_busecc_pend (access R/W1TS)
  [2] IJ7AM_IPPHY_CBASS_WRAP_0_IJ7AM_IPPHY_SAFE_CBASS_0_J7AM_IPPHY_SAFE_CBASS_EXPORT_J7AM_IPPHY_TO_RC_VBUSP_L0_P2P_BRIDGE_EXPORT_J7AM_IPPHY_TO_RC_VBUSP_L0_BRIDGE_SRC_BUSECC_ENABLE_SET — Interrupt Enable Set Register for Ij7am_ipphy_cbass_wrap_0_Ij7am_ipphy_safe_cbass_0_j7am_ipphy_safe_cbass_export_j7am_ipphy_to_rc_vbusp_l0_p2p_bridge_export_j7am_ipphy_to_rc_vbusp_l0_bridge_src_busecc_pend (access R/W1TS)
  [1] IJ7AM_IPPHY_CBASS_WRAP_0_IJ7AM_IPPHY_CBASS_0_J7AM_IPPHY_CBASS_IJ7AM_IPPHY_SAFE_CBASS_MAIN_0_CBASS_ERR_SLV_P2P_BRIDGE_IJ7AM_IPPHY_SAFE_CBASS_MAIN_0_CBASS_ERR_SLV_BRIDGE_SRC_BUSECC_ENABLE_SET — Interrupt Enable Set Register for Ij7am_ipphy_cbass_wrap_0_Ij7am_ipphy_cbass_0_j7am_ipphy_cbass_Ij7am_ipphy_safe_cbass_main_0_cbass_err_slv_p2p_bridge_Ij7am_ipphy_safe_cbass_main_0_cbass_err_slv_bridge_src_busecc_pend (access R/W1TS)
  [0] IJ7AM_IPPHY_CBASS_WRAP_0_IJ7AM_IPPHY_SAFE_CBASS_0_J7AM_IPPHY_SAFE_CBASS_ISLAVE_SAFETY_GASKET_MAIN_RTI_GPU_0_CFG_P2P_BRIDGE_ISLAVE_SAFETY_GASKET_MAIN_RTI_GPU_0_CFG_BRIDGE_BUSECC_ENABLE_SET — Interrupt Enable Set Register for Ij7am_ipphy_cbass_wrap_0_Ij7am_ipphy_safe_cbass_0_j7am_ipphy_safe_cbass_Islave_safety_gasket_main_rti_gpu_0_cfg_p2p_bridge_Islave_safety_gasket_main_rti_gpu_0_cfg_bridge_busecc_pend (access R/W1TS)
